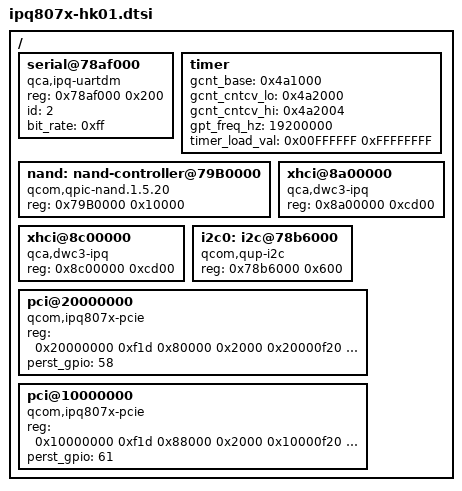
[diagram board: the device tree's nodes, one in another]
/*
 * Copyright (c) 2016, The Linux Foundation. All rights reserved.
 *
 * This program is free software; you can redistribute it and/or modify
 * it under the terms of the GNU General Public License version 2 and
 * only version 2 as published by the Free Software Foundation.
 *
 * This program is distributed in the hope that it will be useful,
 * but WITHOUT ANY WARRANTY; without even the implied warranty of
 * MERCHANTABILITY or FITNESS FOR A PARTICULAR PURPOSE.  See the
 * GNU General Public License for more details.
 */

#include "skeleton.dtsi"
#include <dt-bindings/qcom/gpio-ipq807x.h>

/ {

	serial@78af000 {
		compatible = "qca,ipq-uartdm";
		reg = <0x78af000 0x200>;
		id = <2>;
		bit_rate = <0xff>;
	};

	timer {
		gcnt_base = <0x4a1000>;
		gcnt_cntcv_lo = <0x4a2000>;
		gcnt_cntcv_hi = <0x4a2004>;
		gpt_freq_hz = <19200000>;
		timer_load_val = <0x00FFFFFF 0xFFFFFFFF>;
	};

	nand: nand-controller@79B0000 {
		#address-cells = <1>;
		#size-cells = <0>;
		compatible = "qcom,qpic-nand.1.5.20";
		reg = <0x79B0000 0x10000>;

	};

	xhci@8a00000 {
		compatible = "qca,dwc3-ipq";
		#address-cells = <1>;
		#size-cells = <1>;
		reg = <0x8a00000 0xcd00>;
	};

	xhci@8c00000 {
		compatible = "qca,dwc3-ipq";
		#address-cells = <1>;
		#size-cells = <1>;
		reg = <0x8c00000 0xcd00>;
	};

	i2c0: i2c@78b6000 {
		compatible = "qcom,qup-i2c";
		#address-cells = <1>;
		#size-cells = <0>;
		reg = <0x78b6000 0x600>;
	};

	pci@20000000 {
		compatible = "qcom,ipq807x-pcie";
		#address-cells = <1>;
		#size-cells = <1>;
		reg = <0x20000000 0xf1d
			0x80000 0x2000
			0x20000f20 0xa8
			0x20300000 0xd00000
			0x20100000 0x100000
			0x01875004 0x40>;
		reg-names = "pci_dbi", "parf", "elbi", "axi_bars",
				"axi_conf", "pci_rst";
		perst_gpio = <58>;
	};

	pci@10000000 {
		compatible = "qcom,ipq807x-pcie";
		#address-cells = <1>;
		#size-cells = <1>;
		reg = <0x10000000 0xf1d
			0x88000 0x2000
			0x10000f20 0xa8
			0x10300000 0xd00000
			0x10100000 0x100000
			0x1876004 0x40>;
		reg-names = "pci_dbi", "parf", "elbi", "axi_bars",
				"axi_conf", "pci_rst";
		perst_gpio = <61>;
	};
};
